# HDSC_HC32F4A0 register map
Vendor: HDSC; Series: ARMCM4; File version: 1.0
CPU: CM4 r0p1, little endian, MPU, FPU, 4 interrupt priority bits
Registers are 32-bit, read-write, reset 0x0 unless marked. A register's access mark holds for its fields unless they carry their own. Offsets are from the block's base; [hi:lo] are bit positions; {n}, {i} and the like mark numbered series.

## USBFS
Base 0x40080000
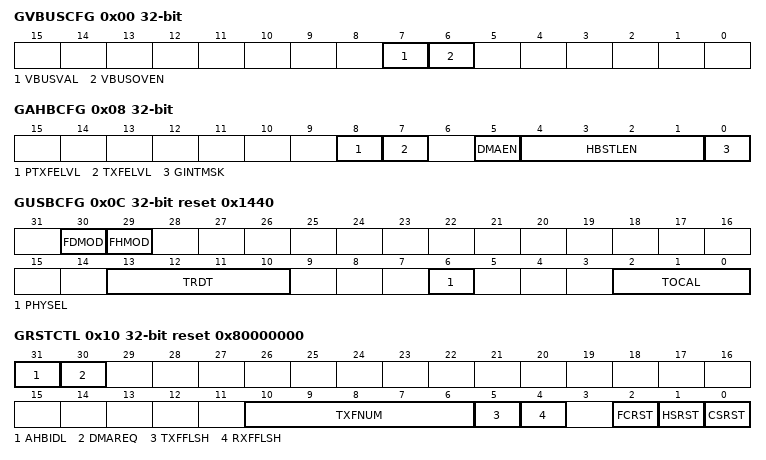
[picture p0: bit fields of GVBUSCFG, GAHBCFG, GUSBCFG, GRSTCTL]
0x00 GVBUSCFG
  [7] VBUSVAL, [6] VBUSOVEN
0x08 GAHBCFG
  [8] PTXFELVL, [7] TXFELVL, [5] DMAEN, [4:1] HBSTLEN, [0] GINTMSK
0x0C GUSBCFG reset 0x1440
  [30] FDMOD, [29] FHMOD, [13:10] TRDT, [6] PHYSEL, [2:0] TOCAL
0x10 GRSTCTL reset 0x80000000
  [31] AHBIDL ro, [30] DMAREQ ro, [10:6] TXFNUM, [5] TXFFLSH, [4] RXFFLSH, [2] FCRST, [1] HSRST, [0] CSRST
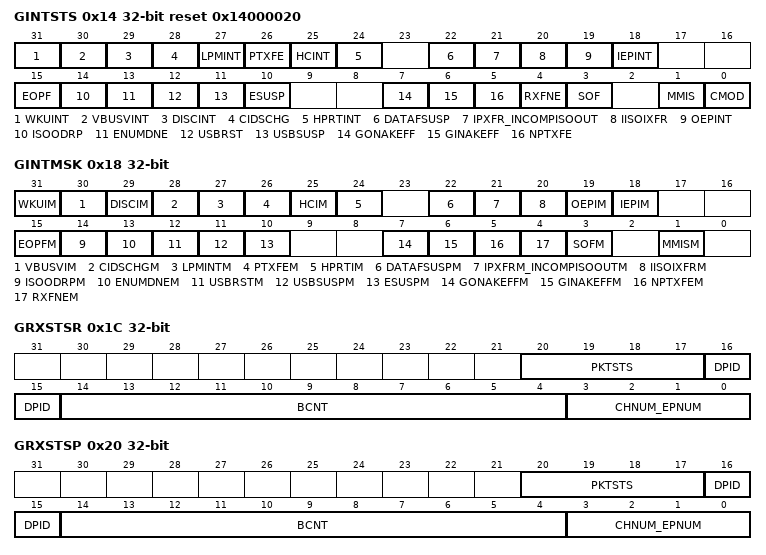
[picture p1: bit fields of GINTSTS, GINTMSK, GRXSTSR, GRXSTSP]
0x14 GINTSTS ro reset 0x14000020
  [31] WKUINT rw, [30] VBUSVINT rw, [29] DISCINT rw, [28] CIDSCHG rw, [27] LPMINT rw, [26] PTXFE, [25] HCINT, [24] HPRTINT, [22] DATAFSUSP rw, [21] IPXFR_INCOMPISOOUT rw, [20] IISOIXFR rw, [19] OEPINT, [18] IEPINT, [15] EOPF rw, [14] ISOODRP rw, [13] ENUMDNE rw, [12] USBRST rw, [11] USBSUSP rw, [10] ESUSP rw, [7] GONAKEFF, [6] GINAKEFF, [5] NPTXFE, [4] RXFNE, [3] SOF rw, [1] MMIS rw, [0] CMOD
0x18 GINTMSK
  [31] WKUIM, [30] VBUSVIM, [29] DISCIM, [28] CIDSCHGM, [27] LPMINTM, [26] PTXFEM, [25] HCIM, [24] HPRTIM, [22] DATAFSUSPM, [21] IPXFRM_INCOMPISOOUTM, [20] IISOIXFRM, [19] OEPIM, [18] IEPIM, [15] EOPFM, [14] ISOODRPM, [13] ENUMDNEM, [12] USBRSTM, [11] USBSUSPM, [10] ESUSPM, [7] GONAKEFFM, [6] GINAKEFFM, [5] NPTXFEM, [4] RXFNEM, [3] SOFM, [1] MMISM
0x1C GRXSTSR ro
  [20:17] PKTSTS, [16:15] DPID, [14:4] BCNT, [3:0] CHNUM_EPNUM
0x20 GRXSTSP ro
  [20:17] PKTSTS, [16:15] DPID, [14:4] BCNT, [3:0] CHNUM_EPNUM
0x24 GRXFSIZ reset 0x280
  [10:0] RXFD
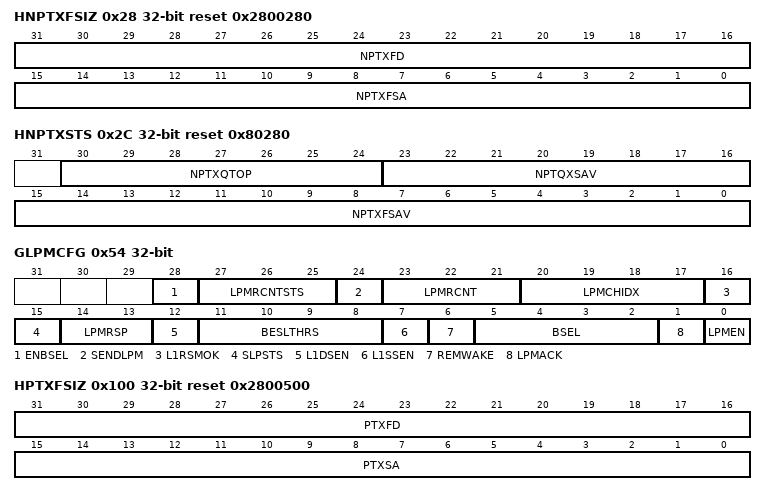
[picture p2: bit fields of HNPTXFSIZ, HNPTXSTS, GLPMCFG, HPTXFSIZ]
0x28 HNPTXFSIZ reset 0x2800280
  [31:16] NPTXFD, [15:0] NPTXFSA
0x2C HNPTXSTS ro reset 0x80280
  [30:24] NPTXQTOP, [23:16] NPTQXSAV, [15:0] NPTXFSAV
0x3C CID reset 0x12345678
0x54 GLPMCFG
  [28] ENBSEL, [27:25] LPMRCNTSTS ro, [24] SENDLPM, [23:21] LPMRCNT, [20:17] LPMCHIDX, [16] L1RSMOK ro, [15] SLPSTS ro, [14:13] LPMRSP ro, [12] L1DSEN, [11:8] BESLTHRS, [7] L1SSEN, [6] REMWAKE, [5:2] BSEL, [1] LPMACK, [0] LPMEN
0x100 HPTXFSIZ reset 0x2800500
  [31:16] PTXFD, [15:0] PTXSA
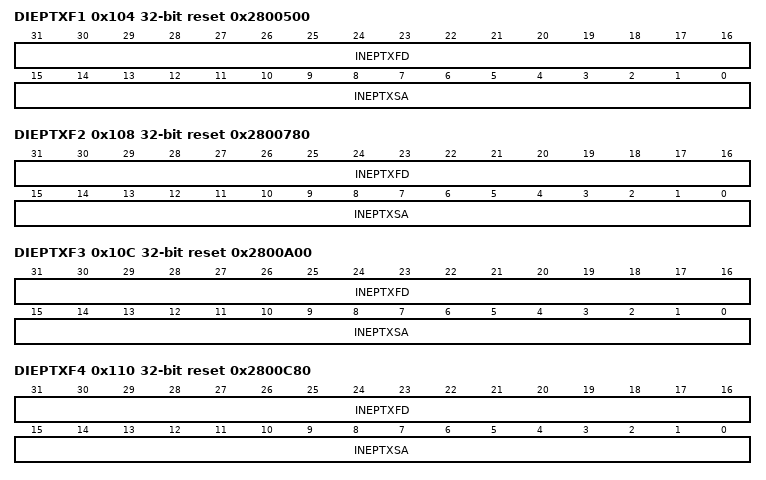
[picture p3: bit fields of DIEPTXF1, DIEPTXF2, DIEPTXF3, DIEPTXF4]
0x104 DIEPTXF1 reset 0x2800500
  [31:16] INEPTXFD, [15:0] INEPTXSA
0x108 DIEPTXF2 reset 0x2800780
  [31:16] INEPTXFD, [15:0] INEPTXSA
0x10C DIEPTXF3 reset 0x2800A00
  [31:16] INEPTXFD, [15:0] INEPTXSA
0x110 DIEPTXF4 reset 0x2800C80
  [31:16] INEPTXFD, [15:0] INEPTXSA
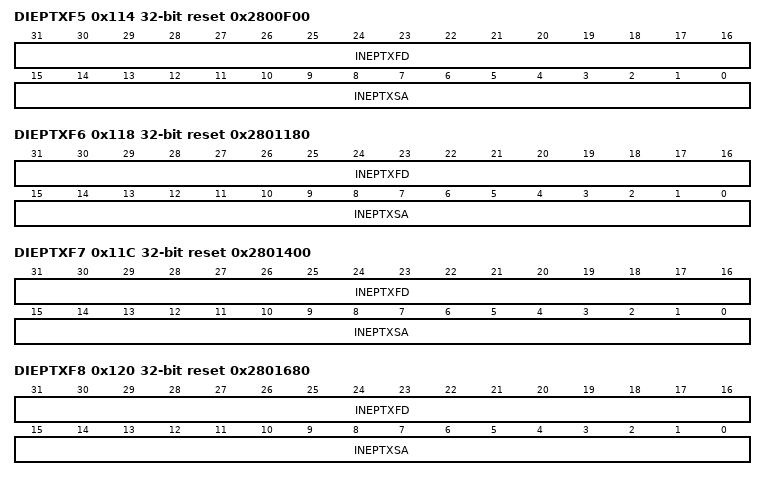
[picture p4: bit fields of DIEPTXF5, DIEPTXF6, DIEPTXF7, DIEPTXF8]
0x114 DIEPTXF5 reset 0x2800F00
  [31:16] INEPTXFD, [15:0] INEPTXSA
0x118 DIEPTXF6 reset 0x2801180
  [31:16] INEPTXFD, [15:0] INEPTXSA
0x11C DIEPTXF7 reset 0x2801400
  [31:16] INEPTXFD, [15:0] INEPTXSA
0x120 DIEPTXF8 reset 0x2801680
  [31:16] INEPTXFD, [15:0] INEPTXSA
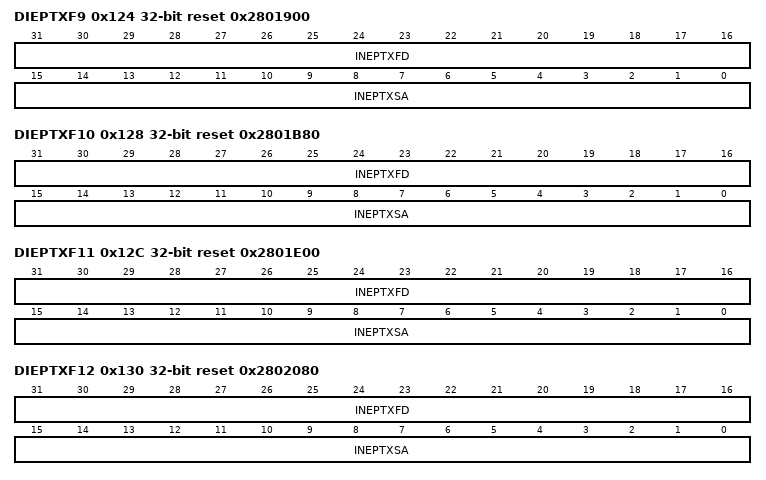
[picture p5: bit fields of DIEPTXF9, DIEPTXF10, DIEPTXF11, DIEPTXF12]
0x124 DIEPTXF9 reset 0x2801900
  [31:16] INEPTXFD, [15:0] INEPTXSA
0x128 DIEPTXF10 reset 0x2801B80
  [31:16] INEPTXFD, [15:0] INEPTXSA
0x12C DIEPTXF11 reset 0x2801E00
  [31:16] INEPTXFD, [15:0] INEPTXSA
0x130 DIEPTXF12 reset 0x2802080
  [31:16] INEPTXFD, [15:0] INEPTXSA
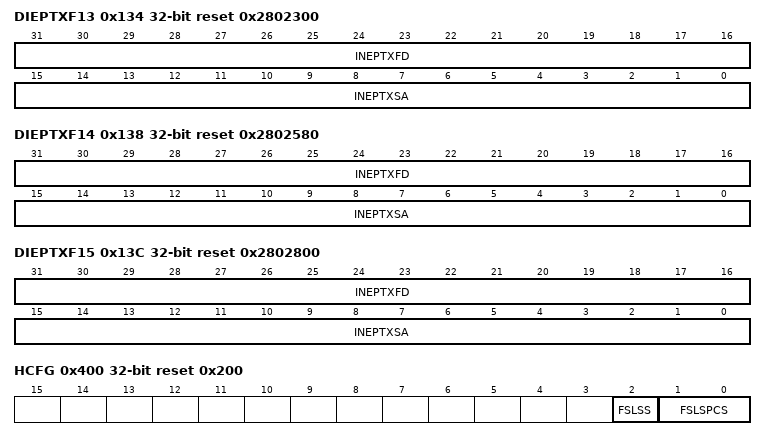
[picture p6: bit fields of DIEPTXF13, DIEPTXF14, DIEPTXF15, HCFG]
0x134 DIEPTXF13 reset 0x2802300
  [31:16] INEPTXFD, [15:0] INEPTXSA
0x138 DIEPTXF14 reset 0x2802580
  [31:16] INEPTXFD, [15:0] INEPTXSA
0x13C DIEPTXF15 reset 0x2802800
  [31:16] INEPTXFD, [15:0] INEPTXSA
0x400 HCFG reset 0x200
  [2] FSLSS, [1:0] FSLSPCS
0x404 HFIR reset 0xEA60
  [15:0] FRIVL
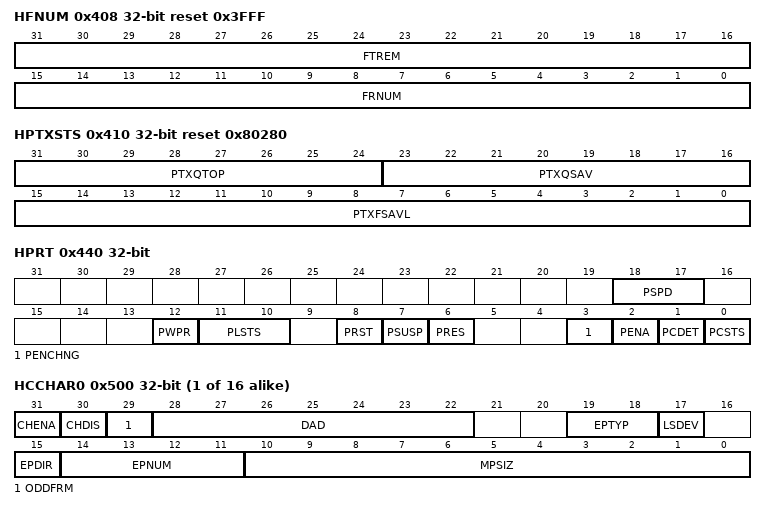
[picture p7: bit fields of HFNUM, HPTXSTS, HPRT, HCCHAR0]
0x408 HFNUM ro reset 0x3FFF
  [31:16] FTREM, [15:0] FRNUM
0x410 HPTXSTS ro reset 0x80280
  [31:24] PTXQTOP, [23:16] PTXQSAV, [15:0] PTXFSAVL
0x414 HAINT ro
  [15:0] HAINT
0x418 HAINTMSK
  [15:0] HAINTM
0x440 HPRT ro
  [18:17] PSPD, [12] PWPR rw, [11:10] PLSTS, [8] PRST rw, [7] PSUSP rw, [6] PRES rw, [3] PENCHNG rw, [2] PENA rw, [1] PCDET rw, [0] PCSTS
{0x500+0x20*i} HCCHAR{i} (i=0..15)
  [31] CHENA, [30] CHDIS, [29] ODDFRM, [28:22] DAD, [19:18] EPTYP ro, [17] LSDEV, [15] EPDIR, [14:11] EPNUM, [10:0] MPSIZ
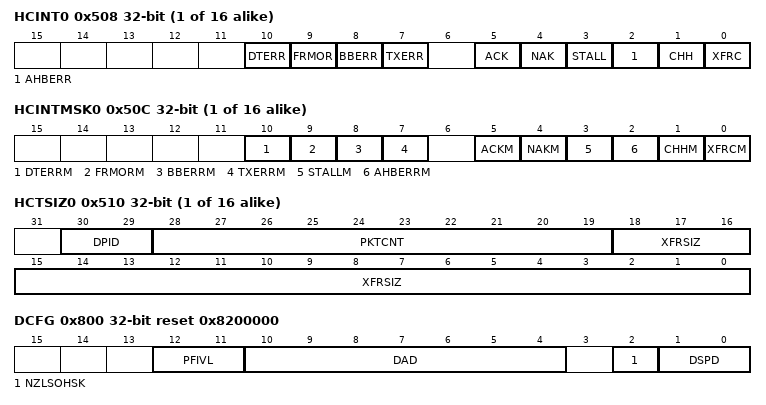
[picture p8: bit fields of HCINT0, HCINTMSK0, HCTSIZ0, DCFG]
{0x508+0x20*i} HCINT{i} (i=0..15)
  [10] DTERR, [9] FRMOR, [8] BBERR, [7] TXERR, [5] ACK, [4] NAK, [3] STALL, [2] AHBERR, [1] CHH, [0] XFRC
{0x50C+0x20*i} HCINTMSK{i} (i=0..15)
  [10] DTERRM, [9] FRMORM, [8] BBERRM, [7] TXERRM, [5] ACKM, [4] NAKM, [3] STALLM, [2] AHBERRM, [1] CHHM, [0] XFRCM
{0x510+0x20*i} HCTSIZ{i} (i=0..15)
  [30:29] DPID, [28:19] PKTCNT, [18:0] XFRSIZ
{0x514+0x20*i} HCDMA{i} (i=0..15)
0x800 DCFG reset 0x8200000
  [12:11] PFIVL, [10:4] DAD, [2] NZLSOHSK, [1:0] DSPD
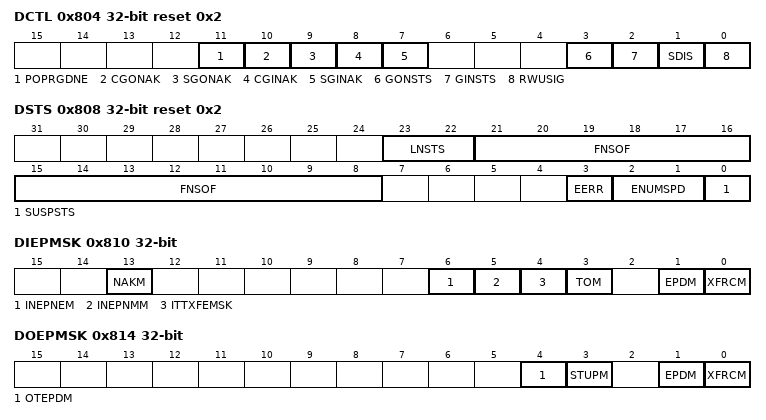
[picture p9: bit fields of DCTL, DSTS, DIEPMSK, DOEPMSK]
0x804 DCTL reset 0x2
  [11] POPRGDNE, [10] CGONAK wo, [9] SGONAK wo, [8] CGINAK wo, [7] SGINAK wo, [3] GONSTS ro, [2] GINSTS ro, [1] SDIS, [0] RWUSIG
0x808 DSTS ro reset 0x2
  [23:22] LNSTS, [21:8] FNSOF, [3] EERR, [2:1] ENUMSPD, [0] SUSPSTS
0x810 DIEPMSK
  [13] NAKM, [6] INEPNEM, [5] INEPNMM, [4] ITTXFEMSK, [3] TOM, [1] EPDM, [0] XFRCM
0x814 DOEPMSK
  [4] OTEPDM, [3] STUPM, [1] EPDM, [0] XFRCM
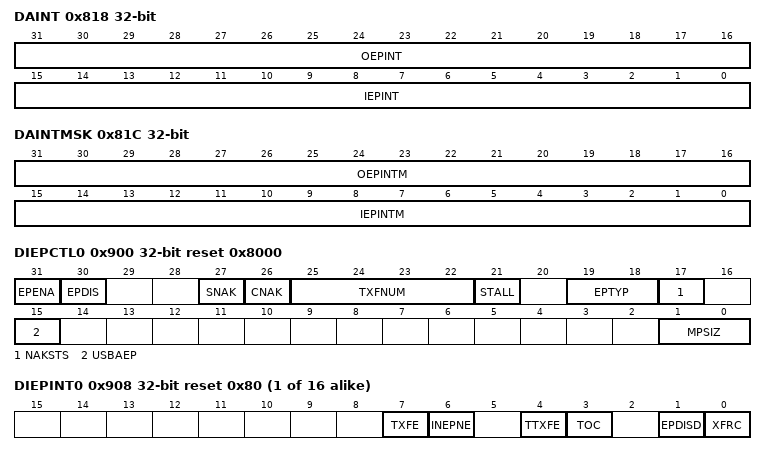
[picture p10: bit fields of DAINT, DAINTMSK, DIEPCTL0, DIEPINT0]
0x818 DAINT
  [31:16] OEPINT, [15:0] IEPINT
0x81C DAINTMSK
  [31:16] OEPINTM, [15:0] IEPINTM
0x834 DIEPEMPMSK
  [15:0] INEPTXFEM
0x900 DIEPCTL0 reset 0x8000
  [31] EPENA, [30] EPDIS, [27] SNAK, [26] CNAK, [25:22] TXFNUM, [21] STALL, [19:18] EPTYP ro, [17] NAKSTS ro, [15] USBAEP ro, [1:0] MPSIZ
{0x908+0x20*i} DIEPINT{i} reset 0x80 (i=0..15)
  [7] TXFE ro, [6] INEPNE, [4] TTXFE, [3] TOC, [1] EPDISD, [0] XFRC
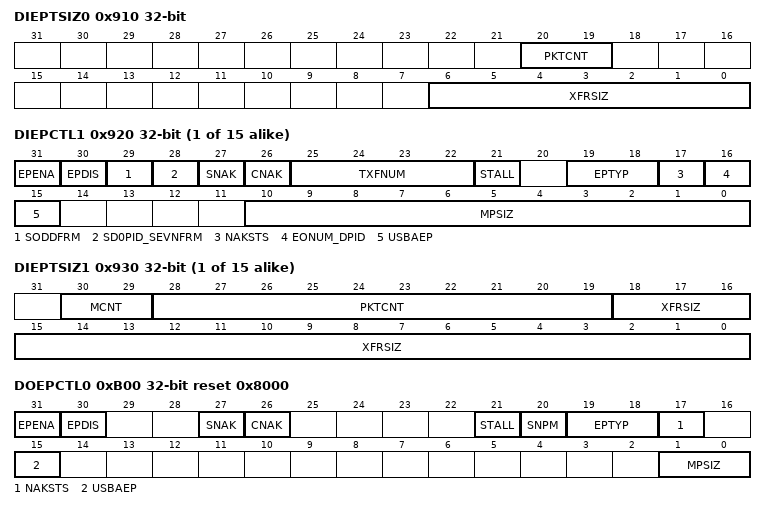
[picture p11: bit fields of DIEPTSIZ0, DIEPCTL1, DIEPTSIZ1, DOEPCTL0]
0x910 DIEPTSIZ0
  [20:19] PKTCNT, [6:0] XFRSIZ
{0x914+0x20*i} DIEPDMA{i} (i=0..15)
{0x918+0x20*i} DTXFSTS{i} ro reset 0x280 (i=0..15)
  [15:0] INEPTFSAV
{0x900+0x20*i} DIEPCTL{i} (i=1..15)
  [31] EPENA, [30] EPDIS, [29] SODDFRM, [28] SD0PID_SEVNFRM, [27] SNAK, [26] CNAK, [25:22] TXFNUM, [21] STALL, [19:18] EPTYP ro, [17] NAKSTS ro, [16] EONUM_DPID ro, [15] USBAEP, [10:0] MPSIZ
{0x910+0x20*i} DIEPTSIZ{i} (i=1..15)
  [30:29] MCNT, [28:19] PKTCNT, [18:0] XFRSIZ
0xB00 DOEPCTL0 reset 0x8000
  [31] EPENA, [30] EPDIS, [27] SNAK, [26] CNAK, [21] STALL, [20] SNPM, [19:18] EPTYP, [17] NAKSTS ro, [15] USBAEP ro, [1:0] MPSIZ
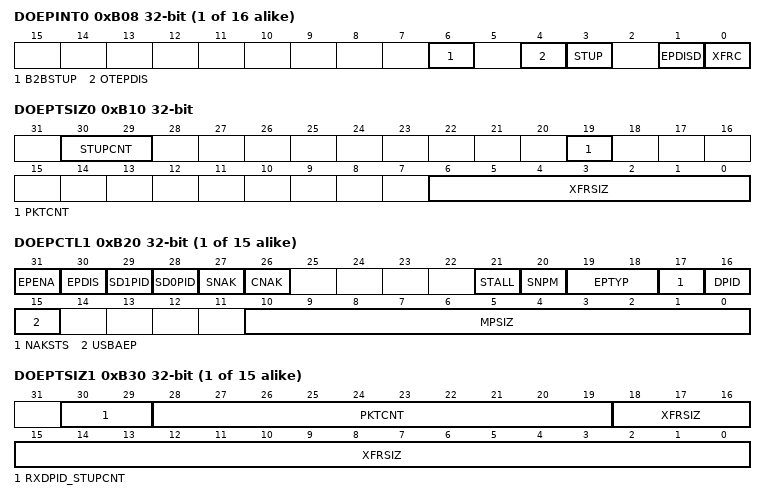
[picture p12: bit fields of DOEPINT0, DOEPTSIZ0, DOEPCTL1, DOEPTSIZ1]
{0xB08+0x20*i} DOEPINT{i} (i=0..15)
  [6] B2BSTUP, [4] OTEPDIS, [3] STUP, [1] EPDISD, [0] XFRC
0xB10 DOEPTSIZ0
  [30:29] STUPCNT, [19] PKTCNT, [6:0] XFRSIZ
{0xB14+0x20*i} DOEPDMA{i} (i=0..15)
{0xB00+0x20*i} DOEPCTL{i} (i=1..15)
  [31] EPENA, [30] EPDIS, [29] SD1PID, [28] SD0PID, [27] SNAK, [26] CNAK, [21] STALL, [20] SNPM, [19:18] EPTYP, [17] NAKSTS ro, [16] DPID ro, [15] USBAEP ro, [10:0] MPSIZ
{0xB10+0x20*i} DOEPTSIZ{i} (i=1..15)
  [30:29] RXDPID_STUPCNT, [28:19] PKTCNT, [18:0] XFRSIZ
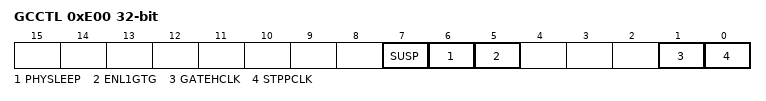
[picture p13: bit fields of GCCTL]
0xE00 GCCTL
  [7] SUSP, [6] PHYSLEEP, [5] ENL1GTG, [1] GATEHCLK, [0] STPPCLK
